AUTOSAR XML (schema 00050)
package /ComponentTypes
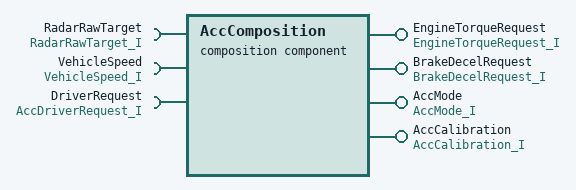
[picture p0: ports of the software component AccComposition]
  composition sw component type AccComposition
    require port RadarRawTarget: required-interface=RadarRawTarget_I
      required-com-specs:
        data-element=RawDistance, init-value=constant-reference=TargetDistance_IV
        data-element=RawRelativeSpeed, init-value=constant-reference=RelativeSpeed_IV
        data-element=RawTargetValid, init-value=constant-reference=RadarTargetValid_IV
    require port VehicleSpeed: nonqueued-receiver-com-spec{data-element=VehicleSpeed, init-value=constant-reference=VehicleSpeed_IV}, required-interface=VehicleSpeed_I
    require port DriverRequest: required-interface=AccDriverRequest_I
      required-com-specs:
        data-element=SetSpeed, init-value=constant-reference=SetSpeed_IV
        data-element=TimeGap, init-value=constant-reference=TimeGap_IV
    4 x provide port:
      EngineTorqueRequest: nonqueued-sender-com-spec{data-element=TorqueRequest, init-value=constant-reference=TorqueRequest_IV}, provided-interface=EngineTorqueRequest_I
      BrakeDecelRequest: nonqueued-sender-com-spec{data-element=DecelRequest, init-value=constant-reference=LongitudinalAccel_IV}, provided-interface=BrakeDecelRequest_I
      AccMode: mode-switch-sender-com-spec{enhanced-mode-api=false, mode-group=accMode, queue-length=1}, provided-interface=AccMode_I
      AccCalibration: provided-com-specs=[{operation=ReadParameter, queue-length=1}, {operation=WriteParameter, queue-length=1}], provided-interface=AccCalibration_I
    component RadarPreProcessing: type=RadarPreProcessing
    component AccController: type=AccController
    component ActuatorArbitration: type=ActuatorArbitration
    connect RadarPreProcessing.RadarTarget -> AccController.RadarTarget
    connect AccController.AccelRequest -> ActuatorArbitration.AccelRequest
    connect AccController.AccMode -> ActuatorArbitration.AccMode
    delegate RadarPreProcessing.RadarRawTarget <-> outer port RadarRawTarget
    delegate RadarPreProcessing.VehicleSpeed <-> outer port VehicleSpeed
    delegate AccController.VehicleSpeed <-> outer port VehicleSpeed
    delegate ActuatorArbitration.VehicleSpeed <-> outer port VehicleSpeed
    delegate AccController.DriverRequest <-> outer port DriverRequest
    delegate AccController.AccCalibration <-> outer port AccCalibration
    delegate AccController.AccMode <-> outer port AccMode
    delegate ActuatorArbitration.EngineTorqueRequest <-> outer port EngineTorqueRequest
    delegate ActuatorArbitration.BrakeDecelRequest <-> outer port BrakeDecelRequest
